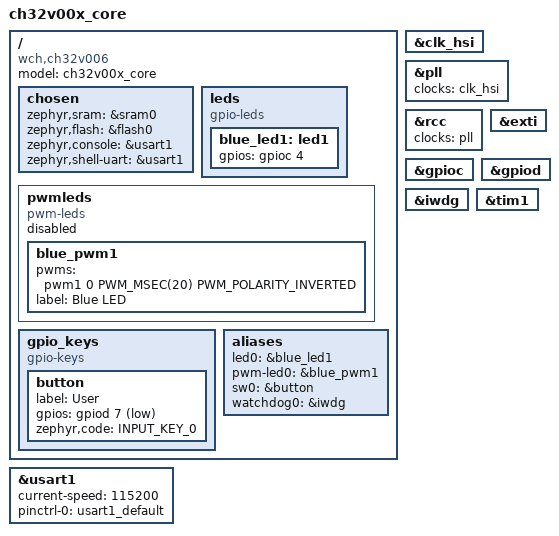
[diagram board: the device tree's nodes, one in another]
/*
 * SPDX-FileCopyrightText: Copyright Michael Hope <michaelh@juju.nz>
 *
 * SPDX-License-Identifier: Apache-2.0
 */

/dts-v1/;

#include <wch/ch32v0/ch32v006f8u.dtsi>
#include "ch32v00x_core-pinctrl.dtsi"

#include <zephyr/dt-bindings/gpio/gpio.h>
#include <zephyr/dt-bindings/input/input-event-codes.h>
#include <zephyr/dt-bindings/pwm/pwm.h>

/ {
	model = "ch32v00x_core";
	compatible = "wch,ch32v006";

	chosen {
		zephyr,sram = &sram0;
		zephyr,flash = &flash0;
		zephyr,console = &usart1;
		zephyr,shell-uart = &usart1;
	};

	leds {
		compatible = "gpio-leds";
		status = "okay";

		blue_led1: led1 {
			gpios = <&gpioc 4 GPIO_ACTIVE_HIGH>;
		};
	};

	pwmleds: pwmleds {
		compatible = "pwm-leds";
		status = "disabled";

		blue_pwm1: blue_pwm1 {
			pwms = <&pwm1 0 PWM_MSEC(20) PWM_POLARITY_INVERTED>;
			label = "Blue LED";
		};
	};

	gpio_keys {
		compatible = "gpio-keys";

		button: button {
			label = "User";
			gpios = <&gpiod 7 (GPIO_PULL_UP | GPIO_ACTIVE_LOW)>;
			zephyr,code = <INPUT_KEY_0>;
		};
	};

	aliases {
		led0 = &blue_led1;
		pwm-led0 = &blue_pwm1;
		sw0 = &button;
		watchdog0 = &iwdg;
	};
};

&clk_hsi {
	status = "okay";
};

&pll {
	clocks = <&clk_hsi>;
	status = "okay";
};

&rcc {
	clocks = <&pll>;
};

&exti {
	status = "okay";
};

&gpioc {
	status = "okay";
};

&gpiod {
	status = "okay";
};

&usart1 {
	status = "okay";
	current-speed = <115200>;
	pinctrl-0 = <&usart1_default>;
	pinctrl-names = "default";
};

&iwdg {
	status = "okay";
};

&tim1 {
	status = "okay";
};
